# EFR32FG14V132F256GM32 register map
File version: 4.0.0
CPU: CM4 r0p1, little endian, MPU, FPU, 3 interrupt priority bits
Registers are 32-bit, read-write, reset 0x0 unless marked. A register's access mark holds for its fields unless they carry their own. Offsets are from the block's base; [hi:lo] are bit positions; {n}, {i} and the like mark numbered series.

## SMU
Base 0x40022000
0x0C IF ro — Interrupt Flag Register
  [0] PPUPRIV — PPU Privilege Interrupt Flag
0x10 IFS wo — Interrupt Flag Set Register
  [0] PPUPRIV — Set PPUPRIV Interrupt Flag
0x14 IFC wo — Interrupt Flag Clear Register
  [0] PPUPRIV — Clear PPUPRIV Interrupt Flag
0x18 IEN — Interrupt Enable Register
  [0] PPUPRIV — PPUPRIV Interrupt Enable
0x40 PPUCTRL — PPU Control Register
  [0] ENABLE
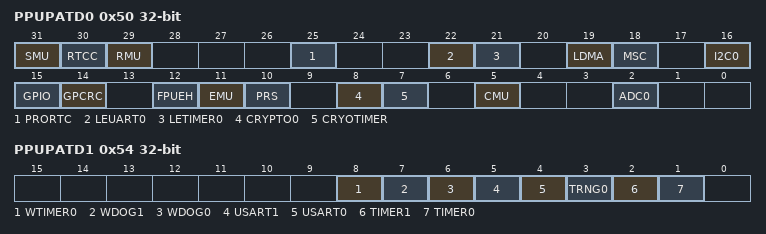
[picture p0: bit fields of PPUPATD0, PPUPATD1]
0x50 PPUPATD0 — PPU Privilege Access Type Descriptor 0
  [31] SMU — Security Management Unit access control bit
  [30] RTCC — Real-Time Counter and Calendar access control bit
  [29] RMU — Reset Management Unit access control bit
  [25] PRORTC — Protocol Real-Time Counter access control bit
  [22] LEUART0 — Low Energy UART 0 access control bit
  [21] LETIMER0 — Low Energy Timer 0 access control bit
  [19] LDMA — Linked Direct Memory Access Controller access control bit
  [18] MSC — Memory System Controller access control bit
  [16] I2C0 — I2C 0 access control bit
  [15] GPIO — General purpose Input/Output access control bit
  [14] GPCRC — General Purpose CRC access control bit
  [12] FPUEH — FPU Exception Handler access control bit
  [11] EMU — Energy Management Unit access control bit
  [10] PRS — Peripheral Reflex System access control bit
  [8] CRYPTO0 — Advanced Encryption Standard Accelerator 0 access control bit
  [7] CRYOTIMER — CRYOTIMER access control bit
  [5] CMU — Clock Management Unit access control bit
  [2] ADC0 — Analog to Digital Converter 0 access control bit
0x54 PPUPATD1 — PPU Privilege Access Type Descriptor 1
  [8] WTIMER0 — Wide Timer 0 access control bit
  [7] WDOG1 — Watchdog 1 access control bit
  [6] WDOG0 — Watchdog 0 access control bit
  [5] USART1 — Universal Synchronous/Asynchronous Receiver/Transmitter 1 access control bit
  [4] USART0 — Universal Synchronous/Asynchronous Receiver/Transmitter 0 access control bit
  [3] TRNG0 — True Random Number Generator 0 access control bit
  [2] TIMER1 — Timer 1 access control bit
  [1] TIMER0 — Timer 0 access control bit
0x90 PPUFS ro — PPU Fault Status
  [6:0] PERIPHID
    2=ADC0 (Analog to Digital Converter 0); 5=CMU (Clock Management Unit); 7=CRYOTIMER; 8=CRYPTO0 (Advanced Encryption Standard Accelerator 0); 10=PRS (Peripheral Reflex System); 11=EMU (Energy Management Unit); 12=FPUEH (FPU Exception Handler); 14=GPCRC (General Purpose CRC); 15=GPIO (General purpose Input/Output); 16=I2C0; 18=MSC (Memory System Controller); 19=LDMA (Linked Direct Memory Access Controller); 21=LETIMER0 (Low Energy Timer 0); 22=LEUART0 (Low Energy UART 0); 25=PRORTC (Protocol Real-Time Counter); 29=RMU (Reset Management Unit); 30=RTCC (Real-Time Counter and Calendar); 31=SMU (Security Management Unit); 33=TIMER0; 34=TIMER1; 35=TRNG0 (True Random Number Generator 0); 36=USART0 (Universal Synchronous/Asynchronous Receiver/Transmitter 0); 37=USART1 (Universal Synchronous/Asynchronous Receiver/Transmitter 1); 38=WDOG0 (Watchdog 0); 39=WDOG1 (Watchdog 1); 40=WTIMER0 (Wide Timer 0)

## TRNG0
Base 0x4001D000
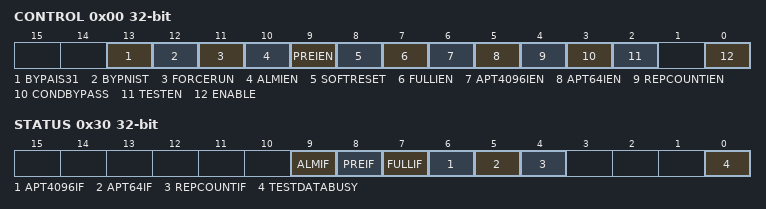
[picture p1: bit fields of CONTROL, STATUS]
0x00 CONTROL — Main Control Register
  [13] BYPAIS31 — AIS31 Start-up Test Bypass.
  [12] BYPNIST — NIST Start-up Test Bypass.
  [11] FORCERUN — Oscillator Force Run
  [10] ALMIEN — Interrupt enable for AIS31 noise alarm
  [9] PREIEN — Interrupt enable for AIS31 preliminary noise alarm
  [8] SOFTRESET — Software Reset
  [7] FULLIEN — Interrupt Enable for FIFO Full
  [6] APT4096IEN — Interrupt Enable for Adaptive Proportion Test Failure (4096-sample Window)
  [5] APT64IEN — Interrupt Enable for Adaptive Proportion Test Failure (64-sample Window)
  [4] REPCOUNTIEN — Interrupt Enable for Repetition Count Test Failure
  [3] CONDBYPASS — Conditioning Bypass
  [2] TESTEN — Test Enable
  [0] ENABLE — TRNG Module Enable
0x04 FIFOLEVEL ro read-has-side-effects
  [31:0] VALUE — FIFO Level
0x0C FIFODEPTH ro reset 0x40
  [31:0] VALUE — FIFO Depth.
{0x10+4i} KEY{i} (i=0..3) — Key Register {i}
  [31:0] VALUE — Key {i}
0x20 TESTDATA
  [31:0] VALUE — Test data input to conditioning function or to the continuous tests
0x30 STATUS
  [9] ALMIF ro — AIS31 Noise Alarm interrupt status
  [8] PREIF — AIS31 Preliminary Noise Alarm interrupt status
  [7] FULLIF ro — FIFO Full Interrupt Status
  [6] APT4096IF ro — Adaptive Proportion test failure (4096-sample window) interrupt status
  [5] APT64IF ro — Adaptive Proportion test failure (64-sample window) interrupt status
  [4] REPCOUNTIF ro — Repetition Count Test Interrupt Status
  [0] TESTDATABUSY ro
0x34 INITWAITVAL reset 0xFF — Initial Wait Counter
  [7:0] VALUE — Wait counter value
0x100 FIFO ro read-has-side-effects — FIFO Data
  [31:0] VALUE — FIFO Read Data

## Notices in the file
# License
Copyright 2021 Silicon Laboratories Inc. www.silabs.com
SPDX-License-Identifier: Zlib
The licensor of this software is Silicon Laboratories Inc.
This software is provided 'as-is', without any express or implied
warranty. In no event will the authors be held liable for any damages
arising from the use of this software.
Permission is granted to anyone to use this software for any purpose,
including commercial applications, and to alter it and redistribute it
freely, subject to the following restrictions:
1. The origin of this software must not be misrepresented; you must not
claim that you wrote the original software. If you use this software
in a product, an acknowledgment in the product documentation would be
appreciated but is not required.
2. Altered source versions must be plainly marked as such, and must not be
misrepresented as being the original software.
3. This notice may not be removed or altered from any source distribution.
